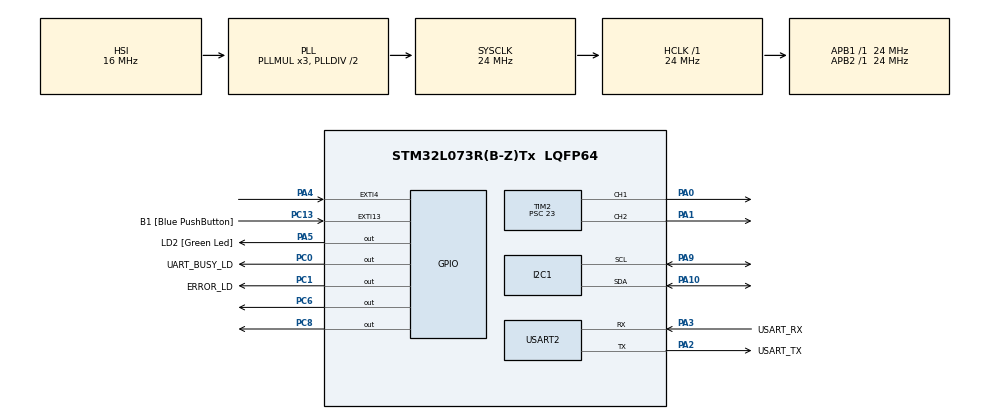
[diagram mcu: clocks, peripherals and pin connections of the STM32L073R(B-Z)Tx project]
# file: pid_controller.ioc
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Dma.I2C1_RX.2.Direction=DMA_PERIPH_TO_MEMORY
Dma.I2C1_RX.2.Instance=DMA1_Channel3
Dma.I2C1_RX.2.MemDataAlignment=DMA_MDATAALIGN_BYTE
Dma.I2C1_RX.2.MemInc=DMA_MINC_ENABLE
Dma.I2C1_RX.2.Mode=DMA_NORMAL
Dma.I2C1_RX.2.PeriphDataAlignment=DMA_PDATAALIGN_BYTE
Dma.I2C1_RX.2.PeriphInc=DMA_PINC_DISABLE
Dma.I2C1_RX.2.Priority=DMA_PRIORITY_LOW
Dma.Request0=USART2_TX
Dma.Request1=USART2_RX
Dma.Request2=I2C1_RX
Dma.USART2_RX.1.Direction=DMA_PERIPH_TO_MEMORY
Dma.USART2_RX.1.Instance=DMA1_Channel5
Dma.USART2_RX.1.MemDataAlignment=DMA_MDATAALIGN_BYTE
Dma.USART2_RX.1.MemInc=DMA_MINC_ENABLE
Dma.USART2_RX.1.Mode=DMA_CIRCULAR
Dma.USART2_RX.1.PeriphDataAlignment=DMA_PDATAALIGN_BYTE
Dma.USART2_RX.1.PeriphInc=DMA_PINC_DISABLE
Dma.USART2_RX.1.Priority=DMA_PRIORITY_LOW
Dma.USART2_TX.0.Direction=DMA_MEMORY_TO_PERIPH
Dma.USART2_TX.0.Instance=DMA1_Channel4
Dma.USART2_TX.0.MemDataAlignment=DMA_MDATAALIGN_BYTE
Dma.USART2_TX.0.MemInc=DMA_MINC_ENABLE
Dma.USART2_TX.0.Mode=DMA_NORMAL
Dma.USART2_TX.0.PeriphDataAlignment=DMA_PDATAALIGN_BYTE
Dma.USART2_TX.0.PeriphInc=DMA_PINC_DISABLE
Dma.USART2_TX.0.Priority=DMA_PRIORITY_LOW
I2C1.Timing=0x00506682
Mcu.Family=STM32L0
Mcu.Name=STM32L073R(B-Z)Tx
Mcu.Package=LQFP64
NVIC.DMA1_Channel2_3_IRQn=true\:0\:0\:false\:false\:true\:false\:true\:true
NVIC.DMA1_Channel4_5_6_7_IRQn=true\:0\:0\:false\:false\:true\:false\:true\:true
NVIC.EXTI4_15_IRQn=true\:0\:0\:false\:false\:true\:true\:true\:true
NVIC.I2C1_IRQn=true\:0\:0\:false\:false\:true\:true\:true\:true
NVIC.USART2_IRQn=true\:0\:0\:false\:false\:true\:true\:true\:true
PA0.Signal=S_TIM2_CH1
PA1.Signal=S_TIM2_CH2
PA10.Mode=I2C
PA10.Signal=I2C1_SDA
PA13.GPIO_Label=TMS
PA13.Signal=SYS_SWDIO
PA14.GPIO_Label=TCK
PA14.Signal=SYS_SWCLK
PA2.GPIO_Label=USART_TX
PA2.Mode=Asynchronous
PA2.Signal=USART2_TX
PA3.GPIO_Label=USART_RX
PA3.Mode=Asynchronous
PA3.Signal=USART2_RX
PA4.Signal=GPXTI4
PA5.GPIO_Label=LD2 [Green Led]
PA5.Signal=GPIO_Output
PA9.Mode=I2C
PA9.Signal=I2C1_SCL
PC0.GPIO_Label=UART_BUSY_LD
PC0.Signal=GPIO_Output
PC1.GPIO_Label=ERROR_LD
PC1.Signal=GPIO_Output
PC13.GPIO_Label=B1 [Blue PushButton]
PC13.GPIO_ModeDefaultEXTI=GPIO_MODE_IT_FALLING
PC13.Signal=GPXTI13
PC14-OSC32_IN.Signal=RCC_OSC32_IN
PC15-OSC32_OUT.Signal=RCC_OSC32_OUT
PC6.Signal=GPIO_Output
PC8.Signal=GPIO_Output
PH0-OSC_IN.GPIO_Label=MCO
PH0-OSC_IN.Signal=RCC_OSC_IN
ProjectManager.HeapSize=0x200
ProjectManager.StackSize=0x400
ProjectManager.TargetToolchain=Makefile
RCC.AHBFreq_Value=24000000
RCC.APB1Freq_Value=24000000
RCC.APB1TimFreq_Value=24000000
RCC.APB2Freq_Value=24000000
RCC.APB2TimFreq_Value=24000000
RCC.HCLKFreq_Value=24000000
RCC.HSE_VALUE=8000000
RCC.HSI16_VALUE=16000000
RCC.HSI48_VALUE=48000000
RCC.HSI_VALUE=16000000
RCC.LSEState=RCC_LSE_ON
RCC.LSE_VALUE=32768
RCC.MSI_VALUE=2097000
RCC.SYSCLKFreq_VALUE=24000000
RCC.SYSCLKSource=RCC_SYSCLKSOURCE_PLLCLK
RCC.VCOOutputFreq_Value=48000000
SH.S_TIM2_CH1.0=TIM2_CH1,PWM Generation1 CH1
SH.S_TIM2_CH2.0=TIM2_CH2,PWM Generation2 CH2
TIM2.Channel-PWM\ Generation1\ CH1=TIM_CHANNEL_1
TIM2.Channel-PWM\ Generation2\ CH2=TIM_CHANNEL_2
TIM2.OCPolarity_1=TIM_OCPOLARITY_HIGH
TIM2.OCPolarity_2=TIM_OCPOLARITY_HIGH
TIM2.Period=20000
TIM2.Prescaler=23
TIM2.Pulse-PWM\ Generation1\ CH1=1500
TIM2.Pulse-PWM\ Generation2\ CH2=1500
USART2.VirtualMode-Asynchronous=VM_ASYNC
VP_TIM2_VS_ClockSourceINT.Mode=Internal
board=NUCLEO-L073RZ

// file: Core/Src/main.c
/* USER CODE BEGIN Header */
/**
  ******************************************************************************
  * @file           : main.c
  * @brief          : Plik zawiera główną pętlę programu
  ******************************************************************************
  * @attention
  *
  * Projekt:
  *   Stabilizator PID
  *
  * Cel:
  *   Stabilizacja piłki na płaskiej powierzchni z użyciem regulatora PID
  *
  * Autorzy:
  *   Adrian Sarwiński
  *   Andrzej Sobota
  *
  ******************************************************************************
  */
/* USER CODE END Header */
#include "main.h"
#include "dma.h"
#include "i2c.h"
#include "tim.h"
#include "usart.h"
#include "gpio.h"

/* USER CODE BEGIN Includes */
#include "balancer_system.h"
/* USER CODE END Includes */

void SystemClock_Config(void);

/* USER CODE BEGIN 0 */
BalancerSystemHandle bs_handle;
/* USER CODE END 0 */

int main(void)
{

  /* MCU Configuration--------------------------------------------------------*/

  /* Reset of all peripherals, Initializes the Flash interface and the Systick. */
  HAL_Init();

  /* Configure the system clock */
  SystemClock_Config();

  /* Initialize all configured peripherals */
  MX_GPIO_Init();
  MX_DMA_Init();
  MX_TIM2_Init();
  MX_USART2_UART_Init();
  MX_I2C1_Init();
  /* USER CODE BEGIN 2 */
  BS_Init(&bs_handle);
  /* USER CODE END 2 */

  /* Infinite loop */
  /* USER CODE BEGIN WHILE */
  while (1)
  {
    BS_RunOnce(&bs_handle);
    /* USER CODE END WHILE */

  }
}

void SystemClock_Config(void)
{
  RCC_OscInitTypeDef RCC_OscInitStruct = {0};
  RCC_ClkInitTypeDef RCC_ClkInitStruct = {0};
  RCC_PeriphCLKInitTypeDef PeriphClkInit = {0};

  /** Configure the main internal regulator output voltage
  */
  __HAL_PWR_VOLTAGESCALING_CONFIG(PWR_REGULATOR_VOLTAGE_SCALE1);

  /** Initializes the RCC Oscillators according to the specified parameters
  * in the RCC_OscInitTypeDef structure.
  */
  RCC_OscInitStruct.OscillatorType = RCC_OSCILLATORTYPE_HSI;
  RCC_OscInitStruct.HSIState = RCC_HSI_ON;
  RCC_OscInitStruct.HSICalibrationValue = RCC_HSICALIBRATION_DEFAULT;
  RCC_OscInitStruct.PLL.PLLState = RCC_PLL_ON;
  RCC_OscInitStruct.PLL.PLLSource = RCC_PLLSOURCE_HSI;
  RCC_OscInitStruct.PLL.PLLMUL = RCC_PLLMUL_3;
  RCC_OscInitStruct.PLL.PLLDIV = RCC_PLLDIV_2;
  if (HAL_RCC_OscConfig(&RCC_OscInitStruct) != HAL_OK)
  {
    Error_Handler();
  }

  /** Initializes the CPU, AHB and APB buses clocks
  */
  RCC_ClkInitStruct.ClockType = RCC_CLOCKTYPE_HCLK|RCC_CLOCKTYPE_SYSCLK
                              |RCC_CLOCKTYPE_PCLK1|RCC_CLOCKTYPE_PCLK2;
  RCC_ClkInitStruct.SYSCLKSource = RCC_SYSCLKSOURCE_PLLCLK;
  RCC_ClkInitStruct.AHBCLKDivider = RCC_SYSCLK_DIV1;
  RCC_ClkInitStruct.APB1CLKDivider = RCC_HCLK_DIV1;
  RCC_ClkInitStruct.APB2CLKDivider = RCC_HCLK_DIV1;

  if (HAL_RCC_ClockConfig(&RCC_ClkInitStruct, FLASH_LATENCY_1) != HAL_OK)
  {
    Error_Handler();
  }
  PeriphClkInit.PeriphClockSelection = RCC_PERIPHCLK_USART2|RCC_PERIPHCLK_I2C1;
  PeriphClkInit.Usart2ClockSelection = RCC_USART2CLKSOURCE_PCLK1;
  PeriphClkInit.I2c1ClockSelection = RCC_I2C1CLKSOURCE_PCLK1;
  if (HAL_RCCEx_PeriphCLKConfig(&PeriphClkInit) != HAL_OK)
  {
    Error_Handler();
  }
}

/* USER CODE BEGIN 4 */
void HAL_UART_RxCpltCallback(UART_HandleTypeDef *huart) {
  BS_UART_RxCpltCallback(&bs_handle, huart);
}

void HAL_I2C_MemRxCpltCallback(I2C_HandleTypeDef *hi2c) {
  BS_I2C_MasterRxCpltCallback(&bs_handle, hi2c);
}

void HAL_GPIO_EXTI_Callback(uint16_t GPIO_Pin) {
  if (GPIO_Pin == GPIO_PIN_4) {
    BS_MPU6050_IntHandle(&bs_handle);
  }
}
/* USER CODE END 4 */

void Error_Handler(void)
{
  __disable_irq();
  while (1)
  {
  }
}
